# MSMC register map
Vendor: Texas Instruments
Peripheral module from a debugger description file (folder 66AK2G0x_66AK2G1x).
Registers are 32-bit, read-only, reset 0x0 unless marked. A register's access mark holds for its fields unless they carry their own. Offsets are as the file gives them; lines under a group give offsets from that group; [hi:lo] are bit positions; {n}, {i} and the like mark numbered series; 'fields as' and 'values as' point back to an identical list; <NAME> marks a mode.

## MSMC
0x00 MSMC_PID reset 0x45000A02
  [31:0] PID — TI internal data. Identifies revision of peripheral.
0x08 MSMC_SMCERRAR
  [31:0] SEADDR — Value = 0-FFFF FFFFhThe lower 32 bits of the 36 bit address used in the accessing the corrupted location is stored here. The upper 4 bits of the 36 bit address in stored in SEEADDR field of the
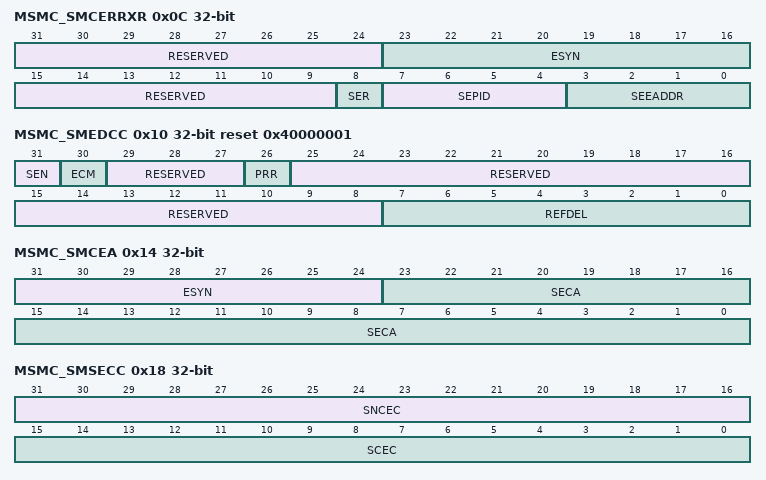
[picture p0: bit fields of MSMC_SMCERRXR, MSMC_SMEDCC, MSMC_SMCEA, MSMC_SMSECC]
0x0C MSMC_SMCERRXR
  [31:24] RESERVED — Reads return 0 and writes have no effect.
  [23:16] ESYN — Value = 0-FFh Logs the syndrome value that identifies the erroneous bit in the data.
  [15:9] RESERVED — Reads return 0 and writes have no effect.
  [8] SER
  [7:4] SEPID — Value = 0-Fh The PrivID associated with the access.
  [3:0] SEEADDR — Value = 0-Fh The upper 4 bits of the 36 bit address used in the accessing the corrupted location is stored here. The lower 32 bits of the 36 bit address in stored in SEADDR field of the MSMC_SMCERRAR register.
0x10 MSMC_SMEDCC access per field reset 0x40000001
  [31] SEN rw — Scrubbing Engine Enable
  [30] ECM rw — Error Correction Mode
  [29:27] RESERVED ro — Reads return 0 and writes have no effect.
  [26] PRR rw — The PRR (Parity RAM Ready) bit shows the status of Parity RAM. Software must consult this bit before making the first read access to MSMC RAM after reset.
  [25:8] RESERVED ro — Reads return 0 and writes have no effect.
  [7:0] REFDEL rw — Value = 0-FFhControls the number of MSMC clock cycles between each scrub burst. To prevent the bursts from the scrubbing engine from posing a significant performance impact, the value in the REFDEL register is pre-scaled by 1024.
0x14 MSMC_SMCEA
  [31:24] ESYN — Value = 0-FFh Logs the syndrome value that identifies the erroneous bit in the data.
  [23:0] SECA — Value = 0-FF FFFFh Scrubbing Error Correctable Address. If the scrubbing engine access detects that a location contents have been corrected, it logs the address.
0x18 MSMC_SMSECC rw
  [31:16] SNCEC — Value = 0-FFFFh Increments the counter on detection of a non-correctable two-bit error.
  [15:0] SCEC — Value = 0-FFFFh Increments the counter on detection of a correctable one-bit error.
0x1C MSMC_SMPFAR
  [31:0] FAULT_ADDRESS — 0-FFFF FFFFh = Fault Access Address
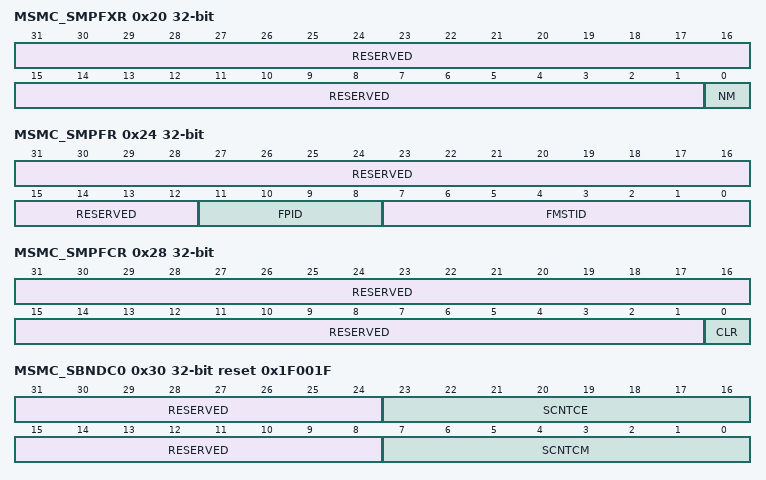
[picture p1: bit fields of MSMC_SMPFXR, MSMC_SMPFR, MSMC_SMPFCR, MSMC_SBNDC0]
0x20 MSMC_SMPFXR
  [31:1] RESERVED — Reads return 0 and writes have no effect.
  [0] NM
0x24 MSMC_SMPFR
  [31:12] RESERVED — Reads return 0 and writes have no effect.
  [11:8] FPID — 0-Fh = PrivID associated with the fault access.
  [7:0] FMSTID — 0-FFh = Master ID associated with the fault access.
0x28 MSMC_SMPFCR access per field
  [31:1] RESERVED ro — Reads return 0 and writes have no effect.
  [0] CLR rw
0x30 MSMC_SBNDC0 access per field reset 0x1F001F
  [31:24] RESERVED ro — Reads return 0 and writes have no effect.
  [23:16] SCNTCE rw — Value = 0-FFh Reload value (pre-scaled by 16) for the starvation counter for DSP requests at the EMIF arbiter.
  [15:8] RESERVED ro — Reads return 0 and writes have no effect.
  [7:0] SCNTCM rw — Value = 0-FFh Reload value for the starvation counters for DSP requests at the RAM bank arbiter.
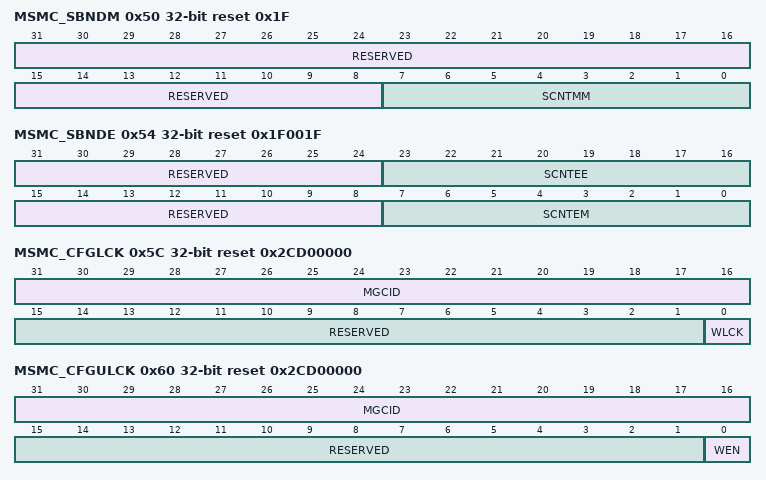
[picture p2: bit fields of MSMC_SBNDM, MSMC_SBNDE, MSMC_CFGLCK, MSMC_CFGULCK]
0x50 MSMC_SBNDM access per field reset 0x1F
  [31:8] RESERVED ro — Reads return 0 and writes have no effect.
  [7:0] SCNTMM rw — Value = 0-FFh Reload value for the starvation counters for SMS requests at the RAM bank arbiter.
0x54 MSMC_SBNDE access per field reset 0x1F001F
  [31:24] RESERVED ro — Reads return 0 and writes have no effect.
  [23:16] SCNTEE rw — Value = 0-FFh Reload value (prescaled by 16) for the starvation counter for SES requests at the EMIF arbiter.
  [15:8] RESERVED ro — Reads return 0 and writes have no effect.
  [7:0] SCNTEM rw — Value = 0-FFh Reload value for the starvation counters for SES requests at the RAM bank arbiter.
0x5C MSMC_CFGLCK access per field reset 0x2CD00000
  [31:16] MGCID wo — 2CD0h = Writing this key value along with setting WLCK to 1 locks the non-MPAX registers.
  [15:1] RESERVED ro — Reads return 0 and writes have no effect.
  [0] WLCK wo
0x60 MSMC_CFGULCK access per field reset 0x2CD00000
  [31:16] MGCID wo — 2CD0h = Writing this key value along with setting WEN to 1 unlocks the non-MPAX registers.
  [15:1] RESERVED ro — Reads return 0 and writes have no effect.
  [0] WEN wo
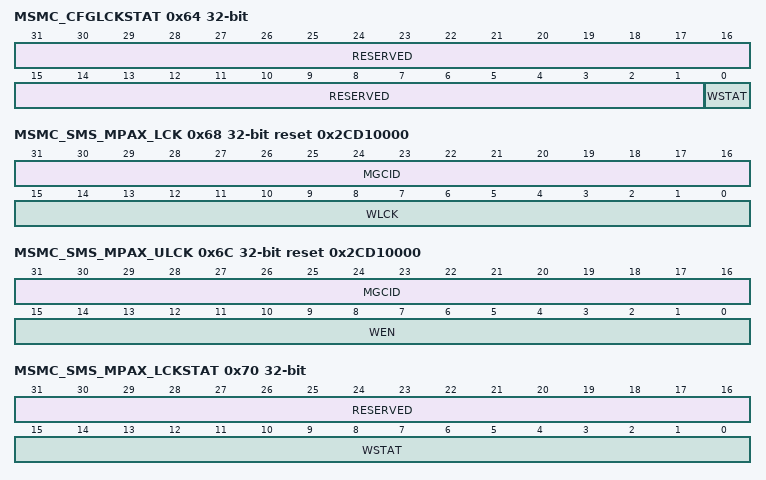
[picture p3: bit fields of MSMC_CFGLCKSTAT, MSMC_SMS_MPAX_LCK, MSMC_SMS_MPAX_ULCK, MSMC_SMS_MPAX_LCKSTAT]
0x64 MSMC_CFGLCKSTAT
  [31:1] RESERVED — Reads return 0 and writes have no effect.
  [0] WSTAT — Indicates the lock's current status.
0x68 MSMC_SMS_MPAX_LCK wo reset 0x2CD10000
  [31:16] MGCID — Value = 2CD1h Writing this key value along with setting WLCK[n] to 1 locks the SMS MPAX registers for PrivID n.
  [15:0] WLCK — Value = 0-FFFFh Bit n denotes lock bit for PrivID n. Writing WLCK[n] bit to 0 has no effect. Writing WLCK[n] bit to 1 along with setting MGCID key = 2CD1h locks the SMS MPAX registers for PrivID n.
0x6C MSMC_SMS_MPAX_ULCK wo reset 0x2CD10000
  [31:16] MGCID — Value = 2CD1hWriting this key value along with setting WEN[n] to 1 unlocks the SMS MPAX registers for PrivID n.
  [15:0] WEN — Value = 0-FFFFh Bit n denotes unlock bit for PrivID n. Writing WEN[n] bit to 0 has no effect. Writing WEN[n] bit to 1 along with setting MGCID key = 2CD1h unlocks the SMS MPAX registers for PrivID n.
0x70 MSMC_SMS_MPAX_LCKSTAT
  [31:16] RESERVED — Reads return 0 and writes have no effect.
  [15:0] WSTAT — Value = 0-FFFFh Bit n indicates the lock's current status for PrivID n.
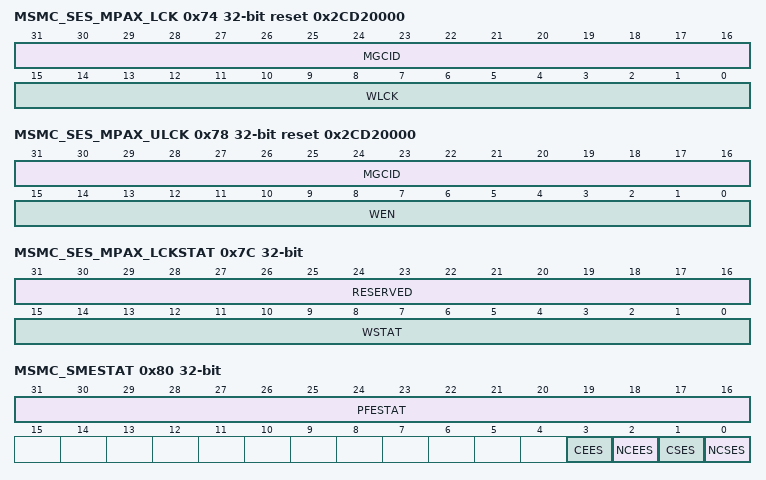
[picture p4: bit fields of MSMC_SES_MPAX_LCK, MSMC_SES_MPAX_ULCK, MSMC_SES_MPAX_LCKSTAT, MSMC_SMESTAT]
0x74 MSMC_SES_MPAX_LCK wo reset 0x2CD20000
  [31:16] MGCID — Value = 2CD2h Writing this key value along with setting WLCK[n] to 1 locks the SES MPAX registers for PrivID n.
  [15:0] WLCK — Value = 0-FFFFh Bit n denotes lock bit for PrivID n. Writing WLCK[n] bit to 0 has no effect. Writing WLCK[n] bit to 1 along with setting MGCID key = 2CD2h locks the SES MPAX registers for PrivID n.
0x78 MSMC_SES_MPAX_ULCK wo reset 0x2CD20000
  [31:16] MGCID — Value = 2CD2h Writing this key value along with setting WEN[n] to 1 unlocks the SES MPAX registers for PrivID n.
  [15:0] WEN — Value = 0-FFFFh Bit n denotes unlock bit for PrivID n. Writing WEN[n] bit to 0 has no effect. Writing WEN[n] bit to 1 along with setting MGCID key = 2CD2h unlocks the SES MPAX registers for PrivID n.
0x7C MSMC_SES_MPAX_LCKSTAT
  [31:16] RESERVED — Reads return 0 and writes have no effect.
  [15:0] WSTAT
0x80 MSMC_SMESTAT
  [31:16] PFESTAT, [3] CEES, [2] NCEES, [1] CSES, [0] NCSES
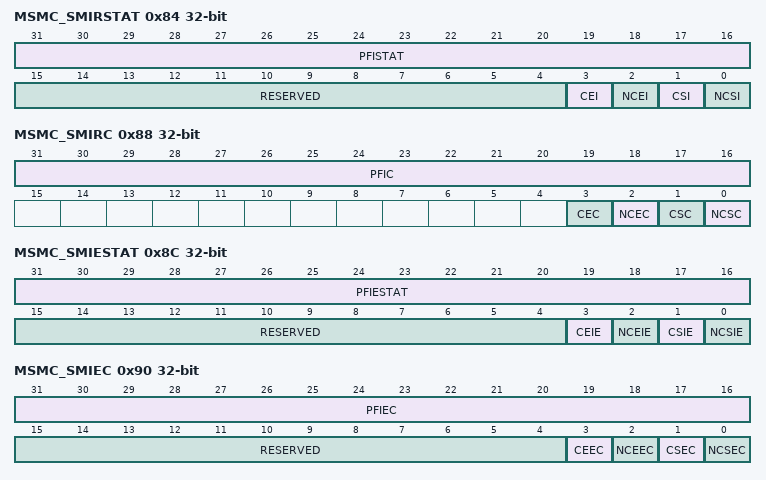
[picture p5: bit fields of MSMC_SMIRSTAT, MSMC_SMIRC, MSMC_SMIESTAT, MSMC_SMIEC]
0x84 MSMC_SMIRSTAT access per field
  [31:16] PFISTAT rw
  [15:4] RESERVED ro — Reads return 0 and writes have no effect.
  [3] CEI rw
  [2] NCEI rw
  [1] CSI rw
  [0] NCSI rw
0x88 MSMC_SMIRC access per field
  [31:16] PFIC wo, [3] CEC wo, [2] NCEC wo, [1] CSC wo, [0] NCSC wo
0x8C MSMC_SMIESTAT access per field
  [31:16] PFIESTAT rw
  [15:4] RESERVED ro — Reads return 0 and writes have no effect.
  [3] CEIE rw
  [2] NCEIE rw
  [1] CSIE rw
  [0] NCSIE rw
0x90 MSMC_SMIEC access per field
  [31:16] PFIEC wo
  [15:4] RESERVED ro — Reads return 0 and writes have no effect.
  [3] CEEC wo
  [2] NCEEC wo
  [1] CSEC wo
  [0] NCSEC wo
0xC4 MSMC_SMNCERRAR
  [31:0] SEADDR — Value = 0-FFFF FFFFh The lower 32 bits of the 36 bit address used in the accessing the corrupted location is stored here. The upper 4 bits of the 36 bit address in stored in SEEADDR field of the MSMC_SMNCERRXR register.
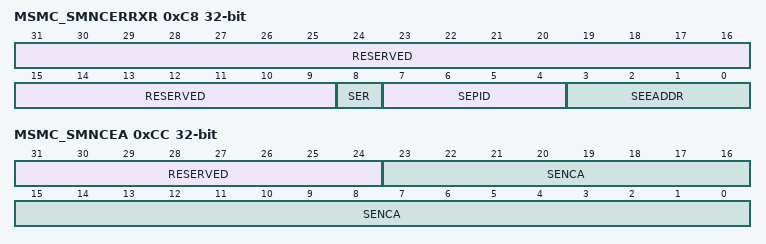
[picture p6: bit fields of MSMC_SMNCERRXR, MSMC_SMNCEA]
0xC8 MSMC_SMNCERRXR
  [31:9] RESERVED — Reads return 0 and writes have no effect.
  [8] SER
  [7:4] SEPID — Value = 0-Fh The PrivID associated with the access.
  [3:0] SEEADDR — Value = 0-Fh The upper 4 bits of the 36 bit address used in the accessing the corrupted location is stored here. The lower 32 bits of the 36 bit address in stored in SEADDR field of the MSMC_SMNCERRAR register.
0xCC MSMC_SMNCEA
  [31:24] RESERVED — Reads return 0 and writes have no effect.
  [23:0] SENCA
